# cc13x2_cc26x2 register map
File version: 2.1
CPU: CM4 r0p1, little endian, MPU, FPU, 3 interrupt priority bits
Registers are 32-bit, read-write, reset 0x0 unless marked. A register's access mark holds for its fields unless they carry their own. Offsets are from the block's base; [hi:lo] are bit positions; {n}, {i} and the like mark numbered series; 'fields as' and 'values as' point back to an identical list.

## ADI2 — Analog Digital Interface his is a generic module for handling register information between digital and analog domain. o see the actual contents connected on the analog side, please see: DI2: ADI_2_REFSYS:ADI_2_REFSYS DI3: ADI_3_REFSYS:ADI_3_REFSYS DI4: ADI_4_AUX:ADI4_AUX
Base 0x40086000
Same registers: ADI3 0x40086200, AUX_ADI4 0x400CB000
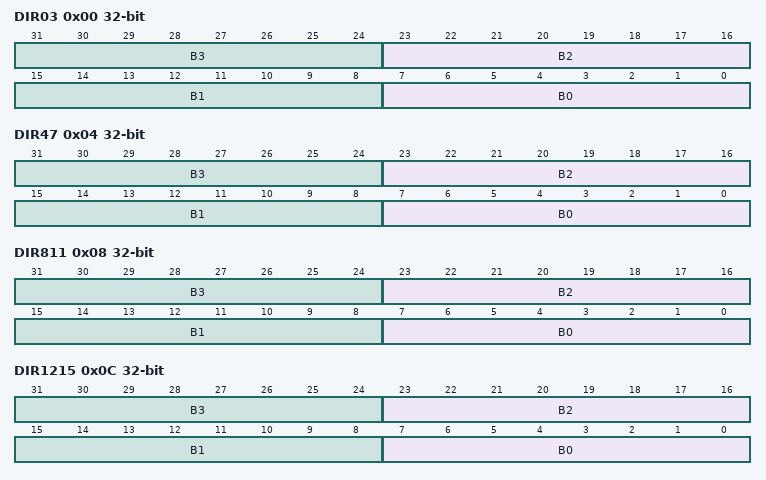
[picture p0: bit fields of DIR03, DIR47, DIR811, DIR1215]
0x00 DIR03 — Direct Access for ADI Byte Offsets 0 to 3
  [8n+7:8n] B{n} (n=0..3)
0x04 DIR47 — Direct Access for ADI Byte Offsets 4 to 7
  [8n+7:8n] B{n} (n=0..3)
0x08 DIR811 — Direct Access for ADI Byte Offsets 8 to 11
  [8n+7:8n] B{n} (n=0..3)
0x0C DIR1215 — Direct Access for ADI Byte Offsets 12 to 15
  [8n+7:8n] B{n} (n=0..3)
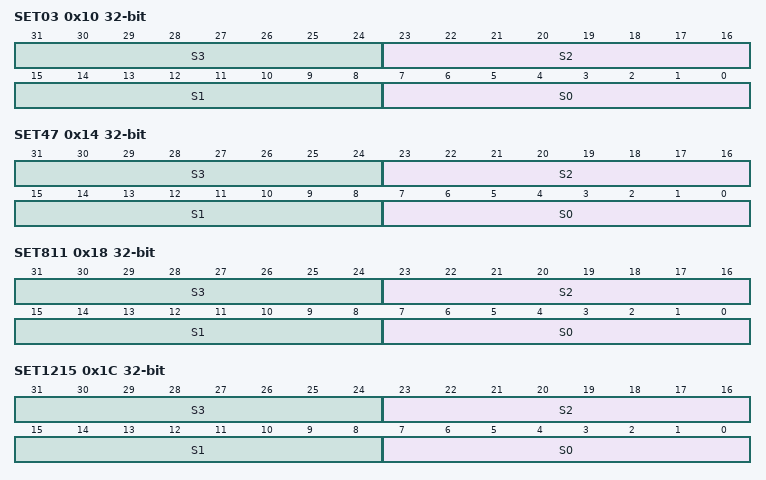
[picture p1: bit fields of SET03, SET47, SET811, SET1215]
0x10 SET03 wo — Set for ADI Byte Offsets 0 to 3
  [8n+7:8n] S{n} (n=0..3)
0x14 SET47 wo — Set for ADI Byte Offsets 4 to 7
  [8n+7:8n] S{n} (n=0..3)
0x18 SET811 wo — Set for ADI Byte Offsets 8 to 11
  [8n+7:8n] S{n} (n=0..3)
0x1C SET1215 wo — Set for ADI Byte Offsets 12 to 15
  [8n+7:8n] S{n} (n=0..3)
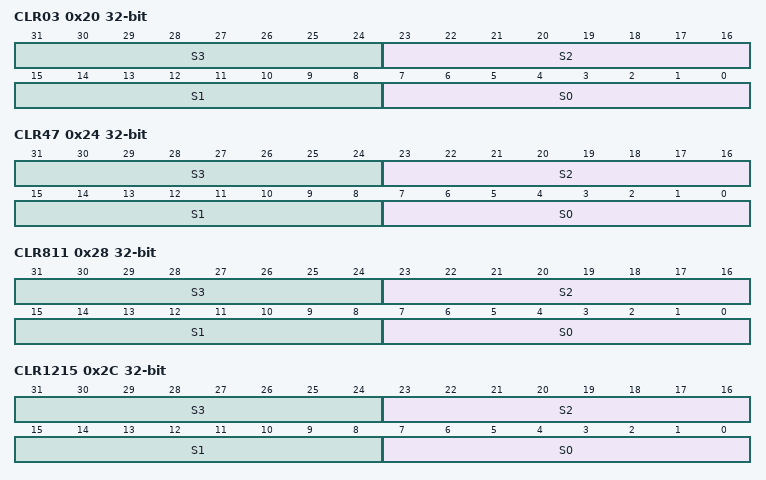
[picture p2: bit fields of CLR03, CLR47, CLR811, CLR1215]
0x20 CLR03 wo — Clear for ADI Byte Offsets 0 to 3
  [8n+7:8n] S{n} (n=0..3)
0x24 CLR47 wo — Clear for ADI Byte Offsets 4 to 7
  [8n+7:8n] S{n} (n=0..3)
0x28 CLR811 wo — Clear for ADI Byte Offsets 8 to 11
  [8n+7:8n] S{n} (n=0..3)
0x2C CLR1215 wo — Clear for ADI Byte Offsets 12 to 15
  [8n+7:8n] S{n} (n=0..3)
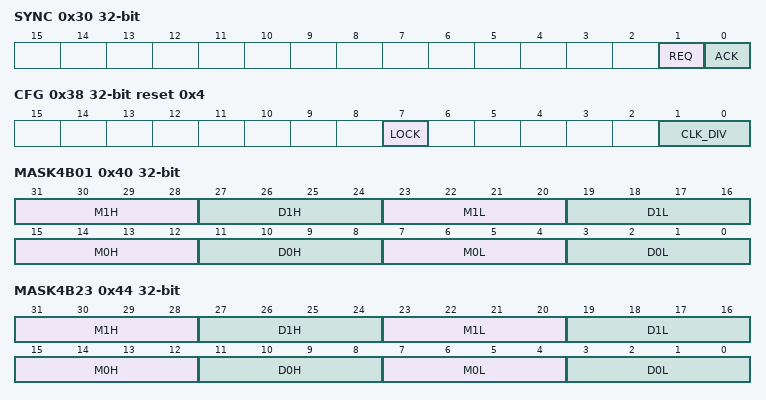
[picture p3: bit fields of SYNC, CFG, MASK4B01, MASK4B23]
0x30 SYNC — Internal. Only to be used through TI provided API.
  [1] REQ, [0] ACK
0x38 CFG reset 0x4 — Internal. Only to be used through TI provided API.
  [7] LOCK, [1:0] CLK_DIV
0x40 MASK4B01 wo — Masked Access (4m/4d), Byte Offsets 0 and 1
  [31:28] M1H, [27:24] D1H, [23:20] M1L, [19:16] D1L, [15:12] M0H, [11:8] D0H, [7:4] M0L, [3:0] D0L
0x44 MASK4B23 wo — Masked Access (4m/4d), Byte Offsets 2 and 3
  fields as MASK4B01
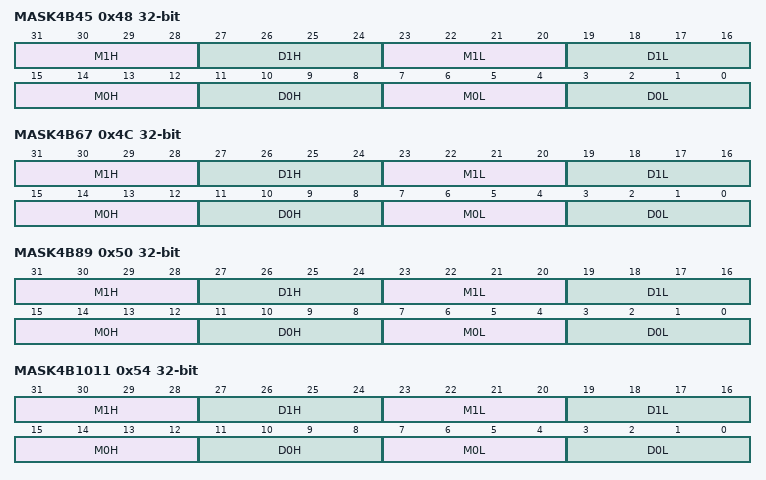
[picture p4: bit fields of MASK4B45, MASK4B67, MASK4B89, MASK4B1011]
0x48 MASK4B45 wo — Masked Access (4m/4d), Byte Offsets 4 and 5
  fields as MASK4B01
0x4C MASK4B67 wo — Masked Access (4m/4d), Byte Offsets 6 and 7
  fields as MASK4B01
0x50 MASK4B89 wo — Masked Access (4m/4d), Byte Offsets 8 and 9
  fields as MASK4B01
0x54 MASK4B1011 wo — Masked Access (4m/4d), Byte Offsets 10 and 11
  fields as MASK4B01
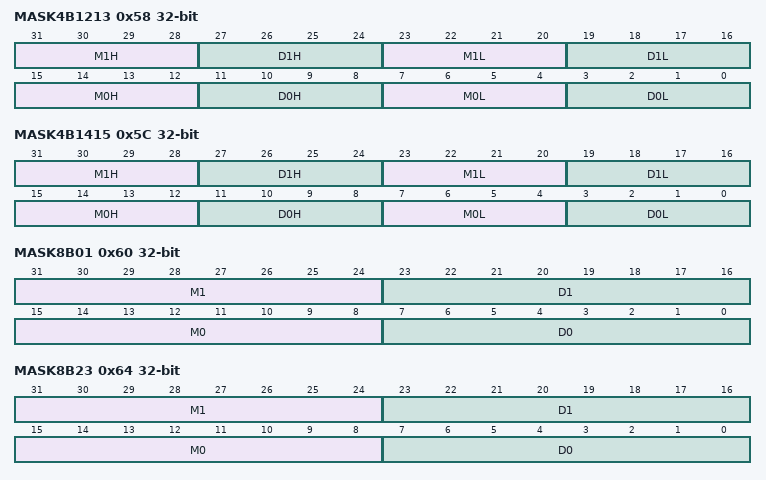
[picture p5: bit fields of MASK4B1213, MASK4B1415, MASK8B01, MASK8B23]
0x58 MASK4B1213 wo — Masked Access (4m/4d), Byte Offsets 12 and 13
  fields as MASK4B01
0x5C MASK4B1415 wo — Masked Access (4m/4d), Byte Offsets 14 and 15
  fields as MASK4B01
0x60 MASK8B01 wo — Masked Access (8m/8d), Byte Offsets 0 and 1
  [31:24] M1, [23:16] D1, [15:8] M0, [7:0] D0
0x64 MASK8B23 wo — Masked Access (8m/8d), Byte Offsets 2 and 3
  [31:24] M1, [23:16] D1, [15:8] M0, [7:0] D0
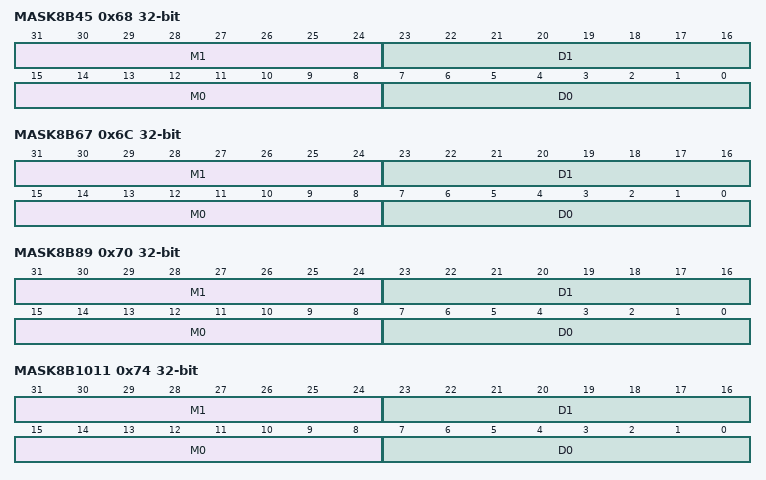
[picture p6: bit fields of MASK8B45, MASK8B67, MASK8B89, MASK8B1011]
0x68 MASK8B45 wo — Masked Access (8m/8d), Byte Offsets 4 and 5
  [31:24] M1, [23:16] D1, [15:8] M0, [7:0] D0
0x6C MASK8B67 wo — Masked Access (8m/8d), Byte Offsets 6 and 7
  [31:24] M1, [23:16] D1, [15:8] M0, [7:0] D0
0x70 MASK8B89 wo — Masked Access (8m/8d), Byte Offsets 8 and 9
  [31:24] M1, [23:16] D1, [15:8] M0, [7:0] D0
0x74 MASK8B1011 wo — Masked Access (8m/8d), Byte Offsets 10 and 11
  [31:24] M1, [23:16] D1, [15:8] M0, [7:0] D0
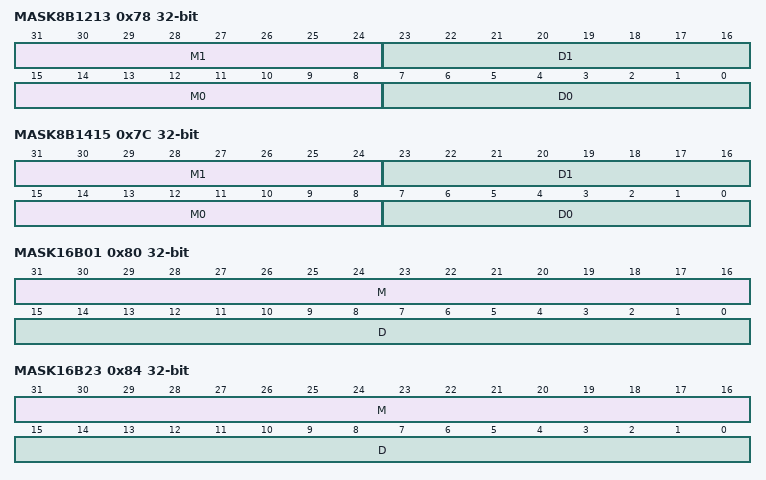
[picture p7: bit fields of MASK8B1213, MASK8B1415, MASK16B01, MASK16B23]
0x78 MASK8B1213 wo — Masked Access (8m/8d), Byte Offsets 12 and 13
  [31:24] M1, [23:16] D1, [15:8] M0, [7:0] D0
0x7C MASK8B1415 wo — Masked Access (8m/8d), Byte Offsets 14 and 15
  [31:24] M1, [23:16] D1, [15:8] M0, [7:0] D0
0x80 MASK16B01 wo — Masked Access (16m/16d), Byte Offsets 0 and 1
  [31:16] M, [15:0] D
0x84 MASK16B23 wo — Masked Access (16m/16d), Byte Offsets 2 and 3
  [31:16] M, [15:0] D
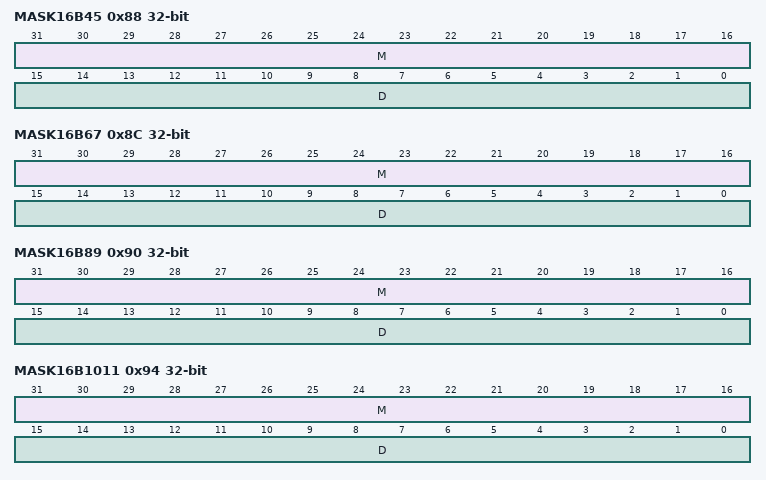
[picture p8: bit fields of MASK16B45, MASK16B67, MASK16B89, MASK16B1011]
0x88 MASK16B45 wo — Masked Access (16m/16d), Byte Offsets 4 and 5
  [31:16] M, [15:0] D
0x8C MASK16B67 wo — Masked Access (16m/16d), Byte Offsets 6 and 7
  [31:16] M, [15:0] D
0x90 MASK16B89 wo — Masked Access (16m/16d), Byte Offsets 8 and 9
  [31:16] M, [15:0] D
0x94 MASK16B1011 wo — Masked Access (16m/16d), Byte Offsets 10 and 11
  [31:16] M, [15:0] D
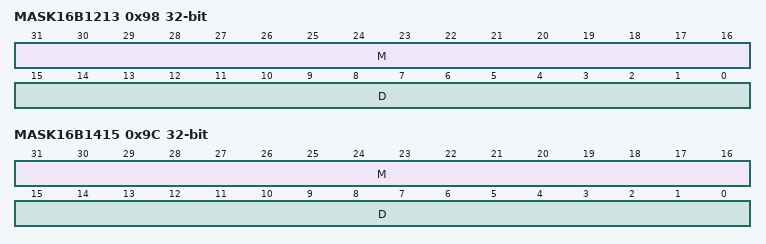
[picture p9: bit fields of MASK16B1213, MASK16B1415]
0x98 MASK16B1213 wo — Masked Access (16m/16d), Byte Offsets 12 and 13
  [31:16] M, [15:0] D
0x9C MASK16B1415 wo — Masked Access (16m/16d), Byte Offsets 14 and 15
  [31:16] M, [15:0] D
